# AT32F435 register map
Vendor: Keil; Series: AT32F435; File version: 1.0
CPU: CM4 r0p1, little endian, no MPU, FPU, 4 interrupt priority bits
Registers are 32-bit, read-write, reset 0x0 unless marked. A register's access mark holds for its fields unless they carry their own. Offsets are from the block's base; [hi:lo] are bit positions; {n}, {i} and the like mark numbered series; 'fields as' and 'values as' point back to an identical list.

## CRM — Clock and reset management
Base 0x40023800
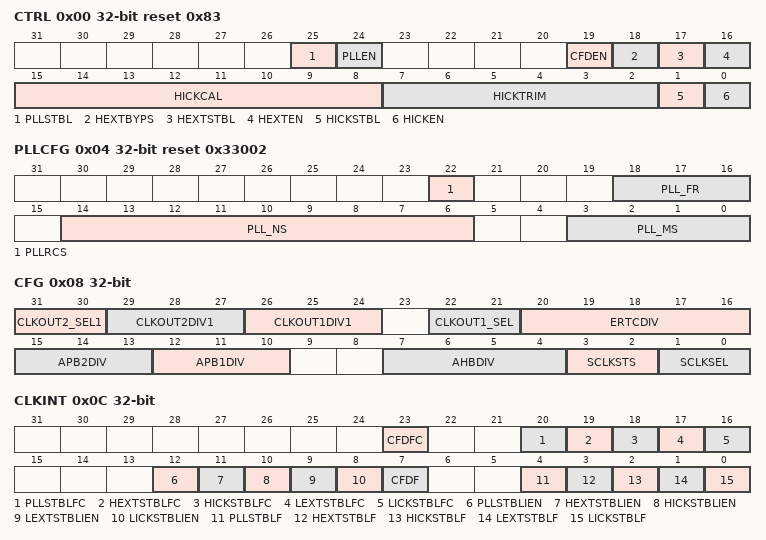
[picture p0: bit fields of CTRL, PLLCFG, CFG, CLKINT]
0x00 CTRL reset 0x83 — Clock control register
  [25] PLLSTBL ro — PLL clock ready flag
    0=NotReady; 1=Ready
  [24] PLLEN — PLL enable
    on read: 0=Disabled (PLL is disabled); 1=Enabled (PLL is enabled) | on write: 0=Disable (PLL disable); 1=Enable (PLL enable)
  [19] CFDEN — Clock failure detection enable
    on read: 0=Disabled (Clock failure detector is disabled); 1=Enabled (Clock failure detector is enabled) | on write: 0=Disable (Clock failure detector disable); 1=Enable (Clock failure detector enable)
  [18] HEXTBYPS — High speed exernal crystal bypass
    on read: 0=Disabled (High speed external crystal bypass is disabled); 1=Enabled (High speed external crystal bypass is enabled) | on write: 0=Disable (High speed external crystal bypass disable); 1=Enable (High speed external crystal bypass enable)
  [17] HEXTSTBL ro — High speed exernal crystal ready flag
    0=NotReady; 1=Ready
  [16] HEXTEN — High speed exernal crystal enable
    on read: 0=Disabled (High speed external crystal is disabled); 1=Enabled (High speed external crystal is enabled) | on write: 0=Disable (High speed external crystal disable); 1=Enable (High speed external crystal enable)
  [15:8] HICKCAL ro — High speed internal clock calibration
  [7:2] HICKTRIM — High speed internal clock trimming
  [1] HICKSTBL ro — High speed internal clock ready flag
    0=NotReady; 1=Ready
  [0] HICKEN — High speed internal clock enable
    on read: 0=Disabled (High speed internal clock is disabled); 1=Enabled (High speed internal clock is enabled) | on write: 0=Disable (High speed internal clock disable); 1=Enable (High speed internal clock enable)
0x04 PLLCFG reset 0x33002 — PLL configuration register (CRM_PLLCFG)
  [22] PLLRCS — PLL reference clock select
  [18:16] PLL_FR — PLL post-division
  [14:6] PLL_NS — PLL frequency multiplication factor
  [3:0] PLL_MS — PLL pre-division
0x08 CFG — Clock configuration register(CRM_CFG)
  [31:30] CLKOUT2_SEL1 — Clock output2 selection1
  [29:27] CLKOUT2DIV1 — Clock output2 division1
  [26:24] CLKOUT1DIV1 — Clock output1 division1
  [22:21] CLKOUT1_SEL — Clock output1 selection
  [20:16] ERTCDIV — HEXT division for ERTC clock
  [15:13] APB2DIV — APB2 division
    0=HCLK (The divided HCLK is used as APB clock); 4=Div2 (HCLK divided by 2); 5=Div4 (HCLK divided by 4); 6=Div8 (HCLK divided by 8); 7=Div16 (HCLK divided by 16)
  [12:10] APB1DIV — APB1 division
    values as APB2DIV
  [7:4] AHBDIV — AHB division
    0=SCLK (The SCLK is used as AHB clock); 8=Div2 (SCLK divided by 2); 9=Div4 (SCLK divided by 4); 10=Div8 (SCLK divided by 8); 11=Div16 (SCLK divided by 16); 12=Div64 (SCLK divided by 64); 13=Div128 (SCLK divided by 128); 14=Div256 (SCLK divided by 256); 15=Div512 (SCLK divided by 512)
  [3:2] SCLKSTS ro — System Clock select Status
    0=HICK (System clock from HICK); 1=HEXT (System clock from HEXT); 2=PLL (System clock from PLL)
  [1:0] SCLKSEL — System clock select
    values as SCLKSTS
0x0C CLKINT — Clock interrupt register (CRM_CLKINT)
  [23] CFDFC wo — Clock failure detection interrupt clear
  [20] PLLSTBLFC wo — PLL ready interrupt clear
  [19] HEXTSTBLFC wo — HEXT ready interrupt clear
  [18] HICKSTBLFC wo — HICK ready interrupt clear
  [17] LEXTSTBLFC wo — LEXT ready interrupt clear
  [16] LICKSTBLFC wo — LICK ready interrupt clear
  [12] PLLSTBLIEN — PLL ready interrupt enable
  [11] HEXTSTBLIEN — HEXT ready interrupt enable
  [10] HICKSTBLIEN — HICK ready interrupt enable
  [9] LEXTSTBLIEN — LEXT ready interrupt enable
  [8] LICKSTBLIEN — LICK ready interrupt enable
  [7] CFDF ro — Clock failure detection interrupt flag
  [4] PLLSTBLF ro — PLL ready interrupt flag
  [3] HEXTSTBLF ro — HEXT ready interrupt flag
  [2] HICKSTBLF ro — HICK ready interrupt flag
  [1] LEXTSTBLF ro — LEXT ready interrupt flag
  [0] LICKSTBLF ro — LICK ready interrupt flag
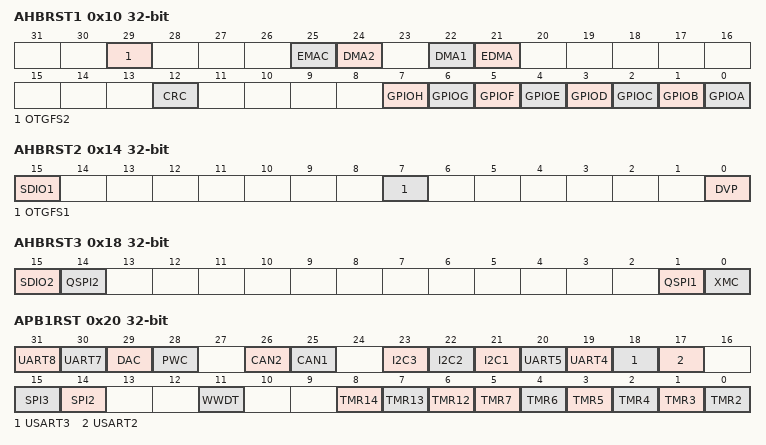
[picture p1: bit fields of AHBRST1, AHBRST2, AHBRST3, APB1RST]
0x10 AHBRST1 — AHB peripheral reset register1 (CRM_AHBRST1)
  [29] OTGFS2 — OTGFS2 interface reset
  [25] EMAC — EMAC reset
  [24] DMA2 — DMA2 reset
  [22] DMA1 — DMA1 reset
  [21] EDMA — EDMA reset
  [12] CRC — CRC reset
  [7] GPIOH — IO port H reset
  [6] GPIOG — IO port G reset
  [5] GPIOF — IO port F reset
  [4] GPIOE — IO port E reset
  [3] GPIOD — IO port D reset
  [2] GPIOC — IO port C reset
  [1] GPIOB — IO port B reset
  [0] GPIOA — IO port A reset
0x14 AHBRST2 — AHB peripheral reset register 2 (CRM_AHBRST2)
  [15] SDIO1 — SDIO1 reset
  [7] OTGFS1 — OTGFS1 reset
  [0] DVP — DVP reset
0x18 AHBRST3 — AHB peripheral reset register 3 (CRM_AHBRST3)
  [15] SDIO2 — SDIO2 reset
  [14] QSPI2 — QSPI2 reset
  [1] QSPI1 — QSPI1 reset
  [0] XMC — XMC reset
0x20 APB1RST — APB1 peripheral reset register (CRM_APB1RST)
  [31] UART8 — UART8 reset
  [30] UART7 — UART7 reset
  [29] DAC — DAC reset
  [28] PWC — PWC reset
  [26] CAN2 — CAN2 reset
  [25] CAN1 — CAN1 reset
  [23] I2C3 — I2C3 reset
  [22] I2C2 — I2C2 reset
  [21] I2C1 — I2C1 reset
  [20] UART5 — UART5 reset
  [19] UART4 — UART4 reset
  [18] USART3 — USART3 reset
  [17] USART2 — USART2 reset
  [15] SPI3 — SPI3 reset
  [14] SPI2 — SPI2 reset
  [11] WWDT — Window watchdog reset
  [8] TMR14 — Timer14 reset
  [7] TMR13 — Timer13 reset
  [6] TMR12 — Timer12 reset
  [n-2] TMR{n} (n=2..7) — Timer{n} reset
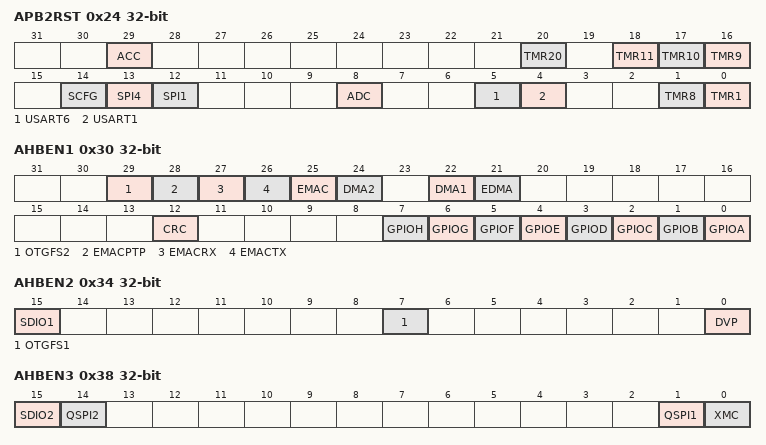
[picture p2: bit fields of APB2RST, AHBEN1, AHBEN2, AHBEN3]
0x24 APB2RST — APB2 peripheral reset register (CRM_APB2RST)
  [29] ACC — ACC reset
  [20] TMR20 — Timer20 reset
  [18] TMR11 — Timer 11 reset
  [17] TMR10 — Timer10 reset
  [16] TMR9 — Timer9 reset
  [14] SCFG — SCFG reset
  [13] SPI4 — SPI4 reset
  [12] SPI1 — SPI1 reset
  [8] ADC — ADC reset
  [5] USART6 — USART6 reset
  [4] USART1 — USART1 reset
  [1] TMR8 — Timer8 reset
  [0] TMR1 — Timer1 reset
0x30 AHBEN1 — AHB Peripheral Clock enable register 1 (CRM_AHBEN1)
  [29] OTGFS2 — OTGFS2 clock enable
  [28] EMACPTP — EMAC PTP clock enable
  [27] EMACRX — EMAC Rx clock enable
  [26] EMACTX — EMAC Tx clock enable
  [25] EMAC — EMAC clock enable
  [24] DMA2 — DMA2 clock enable
  [22] DMA1 — DMA1 clock enable
  [21] EDMA — DMA1 clock enable
  [12] CRC — CRC clock enable
  [7] GPIOH — IO H clock enable
  [6] GPIOG — IO G clock enable
  [5] GPIOF — IO F clock enable
  [4] GPIOE — IO E clock enable
  [3] GPIOD — IO D clock enable
  [2] GPIOC — IO C clock enable
  [1] GPIOB — IO B clock enable
  [0] GPIOA — IO A clock enable
0x34 AHBEN2 — AHB peripheral clock enable register 2 (CRM_AHBEN2)
  [15] SDIO1 — SDIO1 clock enable
  [7] OTGFS1 — OTGFS1 clock enable
  [0] DVP — DVP clock enable
0x38 AHBEN3 — AHB peripheral clock enable register 3 (CRM_AHBEN3)
  [15] SDIO2 — SDIO 2 clock enable
  [14] QSPI2 — QSPI2 clock enable
  [1] QSPI1 — QSPI1 clock enable
  [0] XMC — XMC clock enable
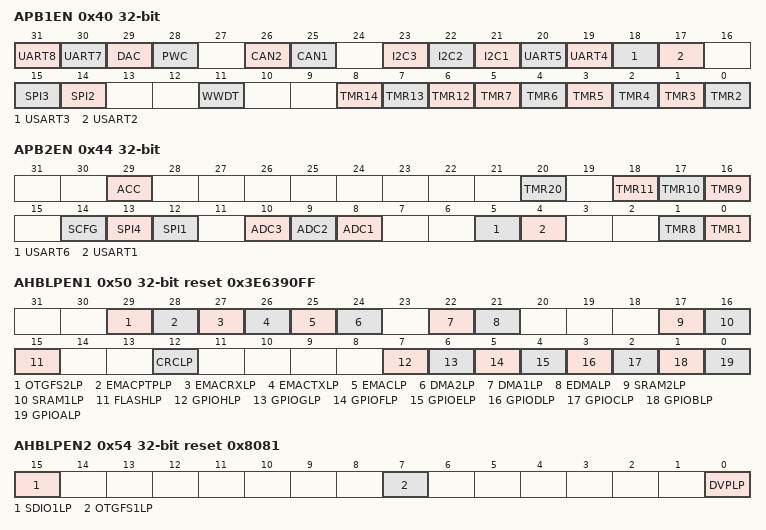
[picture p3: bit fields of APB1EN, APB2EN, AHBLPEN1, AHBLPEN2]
0x40 APB1EN — APB1 peripheral clock enable register (CRM_APB1EN)
  [31] UART8 — UART8 clock enable
  [30] UART7 — UART7 clock enable
  [29] DAC — DAC clock enable
  [28] PWC — PWC clock enable
  [26] CAN2 — CAN2 clock enable
  [25] CAN1 — CAN1 clock enable
  [23] I2C3 — I2C3 clock enable
  [22] I2C2 — I2C2 clock enable
  [21] I2C1 — I2C1 clock enable
  [20] UART5 — UART5 clock enable
  [19] UART4 — UART4 clock enable
  [18] USART3 — USART3 clock enable
  [17] USART2 — USART2 clock enable
  [15] SPI3 — SPI3 clock enable
  [14] SPI2 — SPI2 clock enable
  [11] WWDT — WWDT clock enable
  [8] TMR14 — Timer14 clock enable
  [7] TMR13 — Timer13 clock enable
  [6] TMR12 — Timer12 clock enable
  [n-2] TMR{n} (n=2..7) — Timer{n} clock enable
0x44 APB2EN — APB2 peripheral clock enable register (CRM_APB2EN)
  [29] ACC — ACC clock enable
  [20] TMR20 — Timer20 clock enable
  [18] TMR11 — Timer11 clock enable
  [17] TMR10 — Timer10 clock enable
  [16] TMR9 — Timer9 clock enable
  [14] SCFG — SCFG clock enable
  [13] SPI4 — SPI4 clock enable
  [12] SPI1 — SPI1 clock enable
  [10] ADC3 — ADC3 clock enable
  [9] ADC2 — ADC2 clock enable
  [8] ADC1 — ADC1 clock enable
  [5] USART6 — USART6 clock enable
  [4] USART1 — USART1 clock enable
  [1] TMR8 — Timer8 clock enable
  [0] TMR1 — Timer1 clock enable
0x50 AHBLPEN1 reset 0x3E6390FF — AHB Low-power Peripheral Clock enable register 1 (CRM_AHBLPEN1)
  [29] OTGFS2LP — OTGFS2 clock enable during sleep mode
  [28] EMACPTPLP — EMAC PTP clock enable during sleep mode
  [27] EMACRXLP — EMAC Rx clock enable during sleep mode
  [26] EMACTXLP — EMAC Tx clock enable during sleep mode
  [25] EMACLP — EMAC clock enable during sleep mode
  [24] DMA2LP — DMA2 clock enable during sleep mode
  [22] DMA1LP — DMA1 clock enable during sleep mode
  [21] EDMALP — EDMA clock enable during sleep mode
  [17] SRAM2LP — SRAM2 clock enable during sleep mode
  [16] SRAM1LP — SRAM1 clock enable during sleep mode
  [15] FLASHLP — Flash clock enable during sleep mode
  [12] CRCLP — CRC clock enable during sleep mode
  [7] GPIOHLP — IO H clock enable during sleep mode
  [6] GPIOGLP — IO G clock enable during sleep mode
  [5] GPIOFLP — IO F clock enable during sleep mode
  [4] GPIOELP — IO E clock enable during sleep mode
  [3] GPIODLP — IO D clock enable during sleep mode
  [2] GPIOCLP — IO C clock enable during sleep mode
  [1] GPIOBLP — IO B clock enable during sleep mode
  [0] GPIOALP — IO A clock enable during sleep mode
0x54 AHBLPEN2 reset 0x8081 — AHB peripheral Low-power clock enable register 2 (CRM_AHBLPEN2)
  [15] SDIO1LP — SDIO1 clock enable during sleep mode
  [7] OTGFS1LP — OTGFS1 clock enable during sleep mode
  [0] DVPLP — DVP clock enable during sleep mode
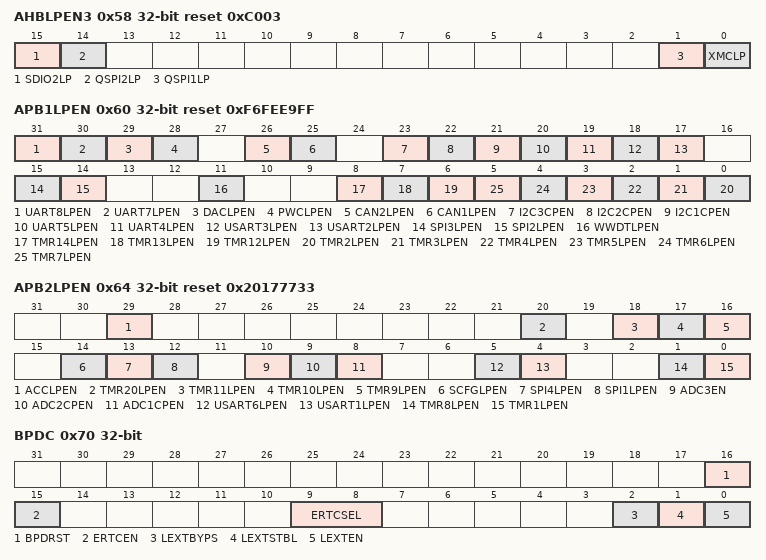
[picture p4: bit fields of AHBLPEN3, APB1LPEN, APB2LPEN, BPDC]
0x58 AHBLPEN3 reset 0xC003 — AHB peripheral Low-power clock enable register 3 (CRM_AHBLPEN3)
  [15] SDIO2LP — SDIO2 clock enable during sleep mode
  [14] QSPI2LP — QSPI2 clock enable during sleep mode
  [1] QSPI1LP — QSPI1 clock enable during sleep mode
  [0] XMCLP — XMC clock enable during sleep mode
0x60 APB1LPEN reset 0xF6FEE9FF — APB1 peripheral Low-power clock enable register (CRM_APB1LPEN)
  [31] UART8LPEN — UART8 clock enable during sleep mode
  [30] UART7LPEN — UART7 clock enable during sleep mode
  [29] DACLPEN — DAC clock enable during sleep mode
  [28] PWCLPEN — PWC clock enable during sleep mode
  [26] CAN2LPEN — CAN2 clock enable during sleep mode
  [25] CAN1LPEN — CAN1 clock enable during sleep mode
  [23] I2C3CPEN — I2C3 clock enable during sleep mode
  [22] I2C2CPEN — I2C2 clock enable during sleep mode
  [21] I2C1CPEN — I2C1 clock enable during sleep mode
  [20] UART5LPEN — UART5 clock enable during sleep mode
  [19] UART4LPEN — UART4 clock enable during sleep mode
  [18] USART3LPEN — USART3 clock enable during sleep mode
  [17] USART2LPEN — USART2 clock enable during sleep mode
  [15] SPI3LPEN — SPI3 clock enable during sleep mode
  [14] SPI2LPEN — SPI2 clock enable during sleep mode
  [11] WWDTLPEN — WWDT clock enable during sleep mode
  [8] TMR14LPEN — Timer14 clock enable during sleep mode
  [7] TMR13LPEN — Timer13 clock enable during sleep mode
  [6] TMR12LPEN — Timer12 clock enable during sleep mode
  [n-2] TMR{n}LPEN (n=2..7) — Timer{n} clock enable during sleep mode
0x64 APB2LPEN reset 0x20177733 — APB2 peripheral Low-power clock enable register (CRM_APB2LPEN)
  [29] ACCLPEN — ACC clock enable during sleep mode
  [20] TMR20LPEN — Timer20 clock enable during sleep mode
  [18] TMR11LPEN — Timer11 clock enable during sleep mode
  [17] TMR10LPEN — Timer10 clock enable during sleep mode
  [16] TMR9LPEN — Timer9 clock enable during sleep mode
  [14] SCFGLPEN — SCFG clock enable during sleep mode
  [13] SPI4LPEN — SPI4 clock enable during sleep mode
  [12] SPI1LPEN — SPI1 clock enable during sleep mode
  [10] ADC3EN — ADC3 clock enable during sleep mode
  [9] ADC2CPEN — ADC2 clock enable during sleep mode
  [8] ADC1CPEN — ADC1 clock enable during sleep mode
  [5] USART6LPEN — USART6 clock enable during sleep mode
  [4] USART1LPEN — USART1 clock enable during sleep mode
  [1] TMR8LPEN — Timer8 clock enable during sleep mode
  [0] TMR1LPEN — Timer1 clock enable during sleep mode
0x70 BPDC — Battery powered domain control register (CRM_BPDC)
  [16] BPDRST — Battery powered domain software reset
  [15] ERTCEN — ERTC clock enable
  [9:8] ERTCSEL — ERTC clock source selection
  [2] LEXTBYPS — Low speed external crystal bypass
  [1] LEXTSTBL ro — Low speed external crystal ready
  [0] LEXTEN — Low speed external crystal enable
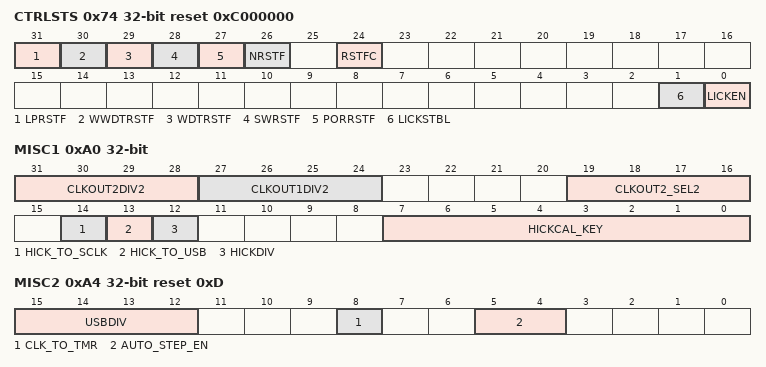
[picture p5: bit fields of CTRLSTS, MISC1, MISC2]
0x74 CTRLSTS reset 0xC000000 — Control/status register (CRM_CTRLSTS)
  [31] LPRSTF — Low-power reset flag
  [30] WWDTRSTF — Window watchdog timer reset flag
  [29] WDTRSTF — Watchdog timer reset flag
  [28] SWRSTF — Software reset flag
  [27] PORRSTF — POR/LVR reset flag
  [26] NRSTF — PIN reset flag
  [24] RSTFC — Reset reset flag
  [1] LICKSTBL ro — Low speed internal clock ready
  [0] LICKEN — Low speed internal clock enable
0xA0 MISC1 — Miscellaneous register1
  [31:28] CLKOUT2DIV2 — Clock output2 division2
  [27:24] CLKOUT1DIV2 — Clock output1 division2
  [19:16] CLKOUT2_SEL2 — Clock output2 select2
  [14] HICK_TO_SCLK — HICK to system clock
  [13] HICK_TO_USB — HICK to usb clock
  [12] HICKDIV — HICK 6 divider selection
  [7:0] HICKCAL_KEY — HICKCAL write key value
0xA4 MISC2 reset 0xD — Miscellaneous register2
  [15:12] USBDIV — USB division
  [8] CLK_TO_TMR — Clock output internal connect to timer10
  [5:4] AUTO_STEP_EN
